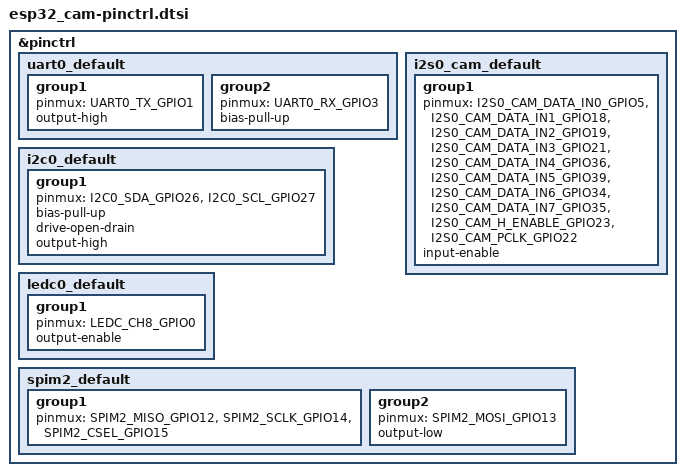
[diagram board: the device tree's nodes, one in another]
/*
 * Copyright (c) 2025 Muhammad Waleed Badar
 *
 * SPDX-License-Identifier: Apache-2.0
 */

#include <zephyr/dt-bindings/pinctrl/esp32-pinctrl.h>

&pinctrl {
	uart0_default: uart0_default {
		group1 {
			pinmux = <UART0_TX_GPIO1>;
			output-high;
		};

		group2 {
			pinmux = <UART0_RX_GPIO3>;
			bias-pull-up;
		};
	};

	i2c0_default: i2c0_default {
		group1 {
			pinmux = <I2C0_SDA_GPIO26>,
				 <I2C0_SCL_GPIO27>;
			bias-pull-up;
			drive-open-drain;
			output-high;
		};
	};

	i2s0_cam_default: i2s0_cam_default {
		group1 {
			pinmux = <I2S0_CAM_DATA_IN0_GPIO5>,
				 <I2S0_CAM_DATA_IN1_GPIO18>,
				 <I2S0_CAM_DATA_IN2_GPIO19>,
				 <I2S0_CAM_DATA_IN3_GPIO21>,
				 <I2S0_CAM_DATA_IN4_GPIO36>,
				 <I2S0_CAM_DATA_IN5_GPIO39>,
				 <I2S0_CAM_DATA_IN6_GPIO34>,
				 <I2S0_CAM_DATA_IN7_GPIO35>,
				 <I2S0_CAM_H_ENABLE_GPIO23>,
				 <I2S0_CAM_PCLK_GPIO22>;
			input-enable;
		};
	};

	ledc0_default: ledc0_default {
		group1 {
			pinmux = <LEDC_CH8_GPIO0>;
			output-enable;
		};
	};

	spim2_default: spim2_default {
		group1 {
			pinmux = <SPIM2_MISO_GPIO12>,
				 <SPIM2_SCLK_GPIO14>,
				 <SPIM2_CSEL_GPIO15>;
		};

		group2 {
			pinmux = <SPIM2_MOSI_GPIO13>;
			output-low;
		};
	};
};
